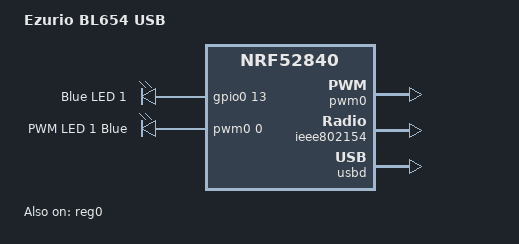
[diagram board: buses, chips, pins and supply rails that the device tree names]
/*
 * Copyright (c) 2017 Linaro Limited
 * Copyright (c) 2018-2023 Nordic Semiconductor ASA
 * Copyright (c) 2025 Ezurio LLC
 *
 * SPDX-License-Identifier: Apache-2.0
 */

/dts-v1/;
#include <nordic/nrf52840_qiaa.dtsi>
#include "bl654_usb-pinctrl.dtsi"

/ {
	model = "Ezurio BL654 USB";
	compatible = "ezurio,bl654-usb-nrf52840";

	chosen {
		zephyr,sram = &sram0;
		zephyr,flash = &flash0;
		zephyr,code-partition = &slot0_partition;
		zephyr,ieee802154 = &ieee802154;
	};

	leds {
		compatible = "gpio-leds";

		led1: led_1 {
			gpios = <&gpio0 13 GPIO_ACTIVE_HIGH>;
			label = "Blue LED 1";
		};
	};

	pwmleds {
		compatible = "pwm-leds";

		led1bluepwm: led_pwm_1 {
			pwms = <&pwm0 0 PWM_MSEC(20) PWM_POLARITY_NORMAL>;
			label = "PWM LED 1 Blue";
		};
	};

	/* These aliases are provided for compatibility with samples */
	aliases {
		led0 = &led1;
		pwm-led0 = &led1bluepwm;
		watchdog0 = &wdt0;
	};
};

&reg0 {
	status = "okay";
};

&reg1 {
	regulator-initial-mode = <NRF5X_REG_MODE_DCDC>;
};

&gpiote {
	status = "okay";
};

&uicr {
	gpio-as-nreset;
};

&gpio0 {
	status = "okay";
};

&gpio1 {
	status = "okay";
};

&pwm0 {
	status = "okay";
	pinctrl-0 = <&pwm0_default>;
	pinctrl-1 = <&pwm0_sleep>;
	pinctrl-names = "default", "sleep";
};

&ieee802154 {
	status = "okay";
};

zephyr_udc0: &usbd {
	compatible = "nordic,nrf-usbd";
	status = "okay";
};

#include <../boards/common/usb/cdc_acm_serial.dtsi>
